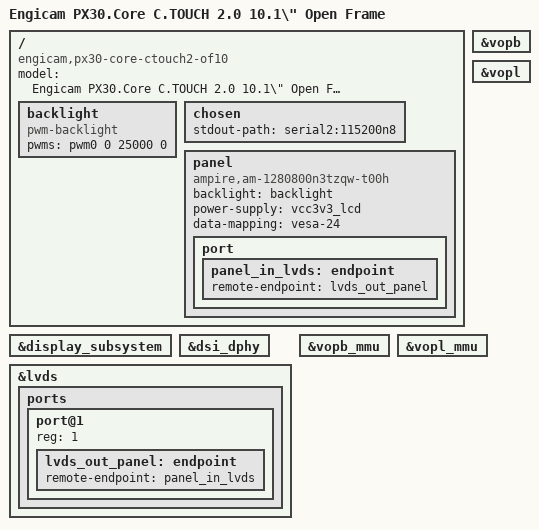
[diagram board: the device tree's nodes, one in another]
// SPDX-License-Identifier: (GPL-2.0+ OR MIT)
/*
 * Copyright (c) 2020 Fuzhou Rockchip Electronics Co., Ltd
 * Copyright (c) 2020 Engicam srl
 * Copyright (c) 2020 Amarula Solutions(India)
 */

/dts-v1/;
#include "px30.dtsi"
#include "px30-engicam-ctouch2.dtsi"
#include "px30-engicam-px30-core.dtsi"

/ {
	model = "Engicam PX30.Core C.TOUCH 2.0 10.1\" Open Frame";
	compatible = "engicam,px30-core-ctouch2-of10", "engicam,px30-core",
		     "rockchip,px30";

	backlight: backlight {
		compatible = "pwm-backlight";
		pwms = <&pwm0 0 25000 0>;
	};

	chosen {
		stdout-path = "serial2:115200n8";
	};

	panel {
		compatible = "ampire,am-1280800n3tzqw-t00h";
		backlight = <&backlight>;
		power-supply = <&vcc3v3_lcd>;
		data-mapping = "vesa-24";

		port {
			panel_in_lvds: endpoint {
				remote-endpoint = <&lvds_out_panel>;
			};
		};
	};
};

&display_subsystem {
	status = "okay";
};

&dsi_dphy {
	status = "okay";
};

&lvds {
	status = "okay";

	ports {
		port@1 {
			reg = <1>;

			lvds_out_panel: endpoint {
				remote-endpoint = <&panel_in_lvds>;
			};
		};
	};
};

&vopb {
	status = "okay";
};

&vopb_mmu {
	status = "okay";
};

&vopl {
	status = "okay";
};

&vopl_mmu {
	status = "okay";
};
